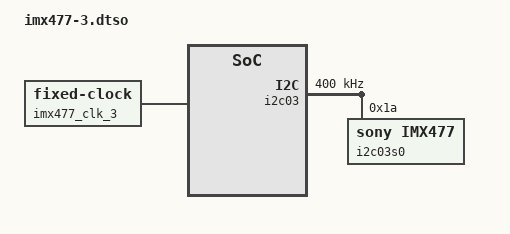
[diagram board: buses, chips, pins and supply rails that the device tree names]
// SPDX-License-Identifier: (GPL-2.0+ OR MIT)
/*
 * Copyright (c) 2024 SiMa ai
 */

/dts-v1/;
/plugin/;

/ {
    fragment@10 {
        target-path = "/"; /* Root node of the base tree */
        __overlay__ {
            imx477_clk_3: csi3_camera-clk {
                compatible = "fixed-clock";
                #clock-cells = <0>;
                clock-frequency = <24000000>;
            };
        };
    };
};

&i2c03 {
	status = "okay";
	clock-frequency = <400000>;

	i2c03s0: sensor@1a {
		compatible = "sony,imx477";
		reg = <0x1a>;
		clocks = <&imx477_clk_3>;
		clock-names = "xclk";
	};
};
